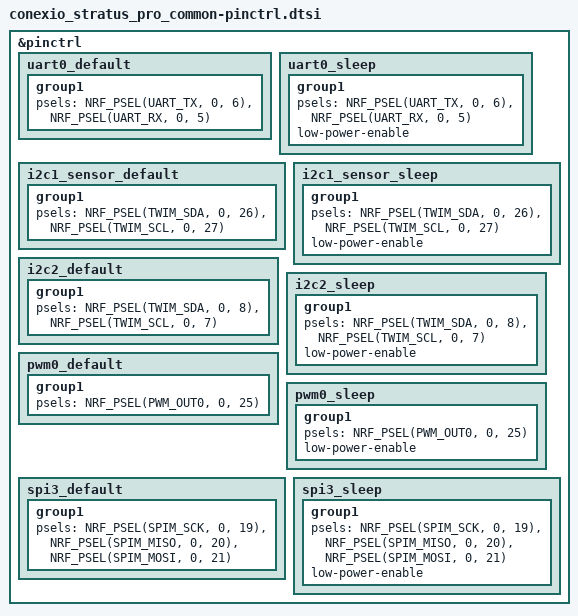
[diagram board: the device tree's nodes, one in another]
/*
 * Copyright (c) 2024 Conexio Technologies, Inc
 * SPDX-License-Identifier: Apache-2.0
 */

&pinctrl {
	/* UART0: match board USB-UART (TX=P0.06, RX=P0.05). Previous mapping was P0.28/P0.27. */
	uart0_default: uart0_default {
		group1 {
			psels = <NRF_PSEL(UART_TX, 0, 6)>,
				<NRF_PSEL(UART_RX, 0, 5)>;
		};
	};

	uart0_sleep: uart0_sleep {
		group1 {
			psels = <NRF_PSEL(UART_TX, 0, 6)>,
				<NRF_PSEL(UART_RX, 0, 5)>;
			low-power-enable;
		};
	};

	/* Sensor bus per Stratus V3 schematic: SHT40 + LIS2DH12 — SCL=P0.27, SDA=P0.26 (TWIM1 / i2c1). */
	i2c1_sensor_default: i2c1_sensor_default {
		group1 {
			psels = <NRF_PSEL(TWIM_SDA, 0, 26)>,
				<NRF_PSEL(TWIM_SCL, 0, 27)>;
		};
	};

	i2c1_sensor_sleep: i2c1_sensor_sleep {
		group1 {
			psels = <NRF_PSEL(TWIM_SDA, 0, 26)>,
				<NRF_PSEL(TWIM_SCL, 0, 27)>;
			low-power-enable;
		};
	};

	i2c2_default: i2c2_default {
		group1 {
			psels = <NRF_PSEL(TWIM_SDA, 0, 8)>,
				<NRF_PSEL(TWIM_SCL, 0, 7)>;
		};
	};

	i2c2_sleep: i2c2_sleep {
		group1 {
			psels = <NRF_PSEL(TWIM_SDA, 0, 8)>,
				<NRF_PSEL(TWIM_SCL, 0, 7)>;
			low-power-enable;
		};
	};

	pwm0_default: pwm0_default {
		group1 {
			psels = <NRF_PSEL(PWM_OUT0, 0, 25)>;
		};
	};

	pwm0_sleep: pwm0_sleep {
		group1 {
			psels = <NRF_PSEL(PWM_OUT0, 0, 25)>;
			low-power-enable;
		};
	};

	spi3_default: spi3_default {
		group1 {
			psels = <NRF_PSEL(SPIM_SCK, 0, 19)>,
				<NRF_PSEL(SPIM_MISO, 0, 20)>,
				<NRF_PSEL(SPIM_MOSI, 0, 21)>;
		};
	};

	spi3_sleep: spi3_sleep {
		group1 {
			psels = <NRF_PSEL(SPIM_SCK, 0, 19)>,
				<NRF_PSEL(SPIM_MISO, 0, 20)>,
				<NRF_PSEL(SPIM_MOSI, 0, 21)>;
			low-power-enable;
		};
	};
};
